# IWRL6432 register map
File version: 1.0
CPU: CM4 1.0, other endian, MPU, FPU, 3 interrupt priority bits
Registers are 32-bit, read-write, reset 0x0 unless marked. A register's access mark holds for its fields unless they carry their own. Offsets are from the block's base; [hi:lo] are bit positions; {n}, {i} and the like mark numbered series.

## HWA_CFG
Base 0x55010000
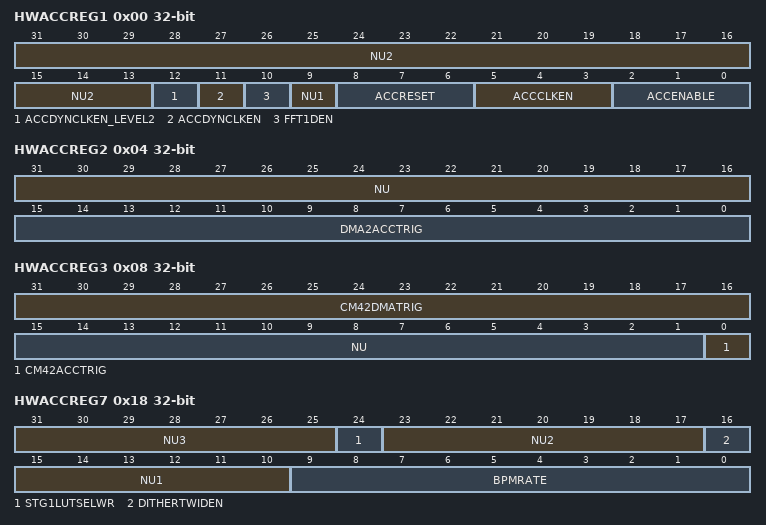
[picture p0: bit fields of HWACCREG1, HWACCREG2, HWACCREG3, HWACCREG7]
0x00 HWACCREG1
  [31:13] NU2
  [12] ACCDYNCLKEN_LEVEL2 — [12:12] Level 2 dynamic clock-gating control :- Setting this register bit to 1 will lead to further power saving by disabling clock during FSM wait state.
  [11] ACCDYNCLKEN — [11:11] Dynamic Clock-gating Control:Setting this register bit to 1 enables the capability to clock gate the Radar Accelerator core IPs (FFT and CFAR-CA datapath,CFAR-OS datapath, memory compression datapath) based on the ParamSet being executed.
  [10] FFT1DEN — [10:10] ADC buffer sharing mode This register is relevant where the Radar Hardware Accelerator is included in a single device along with the mmWave RF front-end. In such a case, during active chirp transmission and inline 1st dimension FFT processing, the ACCEL_MEM0 and ACCEL_MEM1 memories of the accelerator are shared as ping-pong ADC buffers. This register bit needs to be set during this time, so that while the Digital Front End writes ADC samples to the ping buffer, the accelerator automatically accesses (only) the pong buffer, and vice versa. At the end of the active transmission portion of a frame, this bit can be cleared, so that the accelerator has access to all the four local memories independently.
  [9] NU1
  [8:6] ACCRESET — [8:6] Software Reset Control: This register provides software reset control for the Radar Hardware Accelerator. The assertion of these register bits by the main processor will bring the Accelerator Engine to a known reset state. This is mostly applicable for resetting the accelerator in case of unexpected behavior. The sequence to be followed in case software reset is to write 111b to this register and then a 000b
  [5:3] ACCCLKEN — [5:3] Clock-gating Control: This register bit controls the enable/disable for the clock of the Radar Accelerator. This register bit can be set to 0 to clock-gate the accelerator when not using the accelerator. Before enabling the accelerator or before configuring the registers of accelerator, this register bit should be set to 111b first, so that the clock is available.
  [2:0] ACCENABLE — [2:0] Enable/Disable Control: A value of ACC_ENABLE = 111b enables the Radar Hardware Accelerator and any other value of the register keeps the Accelerator Engine in disabled state.
0x04 HWACCREG2
  [31:16] NU
  [15:0] DMA2ACCTRIG — [15:0] DMA trigger register: This register is relevant whenever DMA triggered mode is used (i.e., TRIGMODE = 011b). Whenever a DMA channel has finished copying input samples into the local memory of the accelerator and wants to trigger the accelerator, the procedure to follow is to use a second linked DMA channel to write a 16-bit one-hot signature into this register to trigger the accelerator. In DMA triggered mode, the State Machine keeps monitoring this 16-bit register and waits as long as a specific bit (see DMA2ACC_CHANNEL_TRIGSRC) in this register is zero. The second linked DMA channel writes a one-hot signature that sets the specific bit, so that the State Machine gets triggered and starts the accelerator operations for that parameter-set.
0x08 HWACCREG3
  [31:16] CM42DMATRIG — [31:16] Override accelerator Trigger to DMA.Can be used for triggering the first and second DMA transfer thorugh processor
  [15:1] NU
  [0] CM42ACCTRIG — [0:0] Software trigger bit: This register bit is relevant whenever software triggered mode is used (i.e., TRIGMODE = 001b). The main processor software can set this register bit, so that the State Machine gets triggered and starts the accelerator operations for that parameter-set.
0x0C HWACCREG4
  [31:0] SPARE — [31:0] Spare register
0x10 HWACCREG5
  [31:0] BPMPATTERNMSB — [31:0] BPM pattern MSB: Specifies the BPM pattern to be used to multiply the input samples if BPM removal is enabled
0x14 HWACCREG6
  [31:0] BPMPATTERNLSB — [31:0] BPM pattern LSB: Specifies the BPM pattern to be used to multiply the input samples if BPM removal is enabled
0x18 HWACCREG7
  [31:25] NU3
  [24] STG1LUTSELWR — [24:24] Select Window RAM or Internal RAM: The Internal RAM for Vector Multiplication mode is mapped to the same address space as the Window RAM. Hence, this register bit is required to specify which of these two needs to be selected, when loading the co-efficients via DMA or M4. 0 - Window RAM is selected 1 - Internal RAM for Vector Multiplication mode is selected. Keep this register bit as 0 always, except during the period when Internal RAM needs to be loaded.
  [23:17] NU2
  [16] DITHERTWIDEN — [16:16] Twiddle factor dithering enable: This register-bit is used to enable/disable dithering of twiddle factors in the FFT.
  [15:10] NU1
  [9:0] BPMRATE — [9:0] BPM rate: Specifies the number of input samples corresponding to each BPM bit. Minimum valid value for this register is 1.
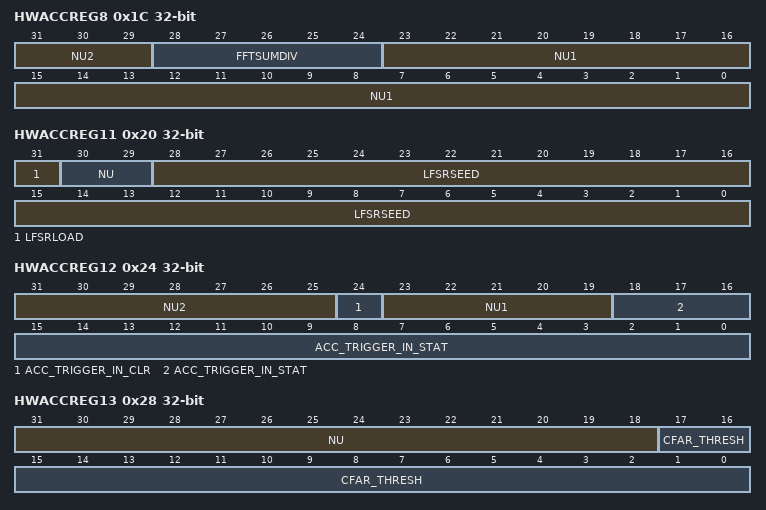
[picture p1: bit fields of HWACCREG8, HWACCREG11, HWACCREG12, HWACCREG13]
0x1C HWACCREG8
  [31:29] NU2
  [28:24] FFTSUMDIV — [28:24] Right-shifting for Sum Statistic: This register specifies how many LSBs to drop to convert the sum statistics to 24-bit value going to the Output Formatter
  [23:0] NU1
0x20 HWACCREG11
  [31] LFSRLOAD — [31:31] To load the LFSR seed, a pulse signal needs to be provided, by writing a 1 to the LFSR_LOAD register-bit. Self clearing
  [30:29] NU
  [28:0] LFSRSEED — [28:0] LFSR seed value (random pattern) for twiddle factor dithering,
0x24 HWACCREG12
  [31:25] NU2
  [24] ACC_TRIGGER_IN_CLR — [24:24] Clear trigger status read-only register: This register-bit when set clears the trigger status register ACC_TRIG_IN_STAT described above
  [23:19] NU1
  [18:0] ACC_TRIGGER_IN_STAT — [18:0] Debug register for trigger status: This is a read-only status register, which indicates the trigger status of the accelerator, i.e., whether a specific DMA trigger or a Ping-pong trigger or a SW trigger was ever received (refer TRIGMODE in HW_ACC_PARAM register set). The MSB 16 bits of this register indicate whether a trigger was received via DMA trigger method. The next two bits (i.e., bit indices 2 and 1) indicate the status of DFE ping-pong switch-based trigger and SW trigger respectively. The LSB bit is always 1 and can be ignored {DMA2ACCTRIG[15:0],adc_buffer_done,CM42ACCTRIG,1}
0x28 HWACCREG13
  [31:18] NU
  [17:0] CFAR_THRESH — [17:0] CFAR Threshold scale factor: This value is used to either multiply or add to the surrounding noise average to determine the threshold used for detection of the present cell under test. If logarithmic CFAR mode is disabled (i.e., in magnitude or magnitude-squared mode), then the register value is multiplied with the surrounding noise average to determine the threshold, else it is added to the surrounding noise average. In the former case, this 18-bit register is interpreted as a 14.4 value. In the latter case (i.e., logarithmic mode), the 18-bit register is interpreted as a 7.11 value.
0x2C HWACCREG14
  [31:0] PARAMDONESTAT — [31:0] Parameter-set done status: This read-only status register can be used by the main processor to see which parameter-sets are complete that led to the interrupt to the main processor. The individual bits in this 32-bit status register indicate which of the 32 parameter-sets have completed.
0x30 HWACCREG15
  [31:0] PARAMDONECLR — [31:0] Status bits in PARAMDONESTAT are not automatically cleared, but they can be individually cleared by writing to 32-bit register PARAMDONECLR.
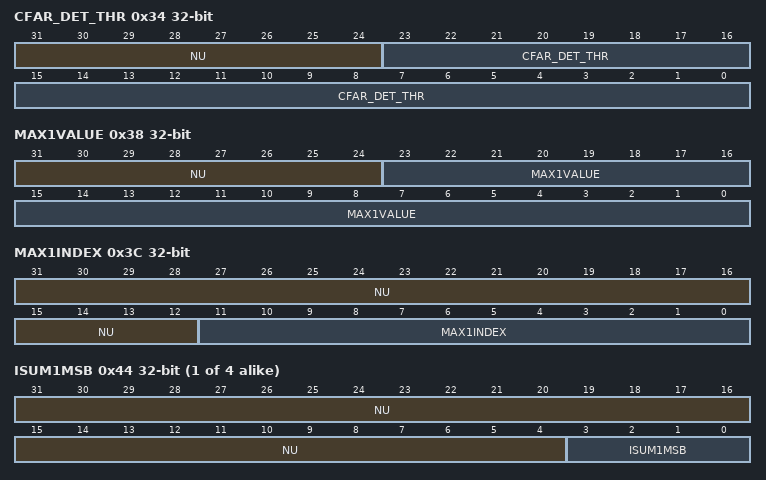
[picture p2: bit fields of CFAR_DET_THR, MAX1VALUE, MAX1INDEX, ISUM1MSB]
0x34 CFAR_DET_THR
  [31:24] NU
  [23:0] CFAR_DET_THR — [23:0] This register is used to specify the threshold used for the detection of the present cell under test during CFAR-CA mode when number of samples for left side and right side noise averaging is 0.
0x38 MAX1VALUE
  [31:24] NU
  [23:0] MAX1VALUE — [23:0] Max value: These registers contain the max value on a per-iteration basis. These registers are meaningful only when Magnitude or Log-Magnitude is enabled. Only the max values for up to four iterations are recorded in these registers. For larger number of iterations, use Statistics output mode (FFT_OUT_MODE in HW_ACC_PARAM register set).
0x3C MAX1INDEX
  [31:12] NU
  [11:0] MAX1INDEX — [11:0] Max index: These registers contain the max index on a per-iteration basis, corresponding to each max value in the MAXn_VALUE registers.
0x40 ISUM1LSB
  [31:0] ISUM1LSB — [31:0] Sum statistics: These registers contain the sum of the I outputs and Q outputs on a per-iteration basis. Only the statistics for up to four iterations are recorded in these registers. For larger number of iterations, use Statistics output mode (FFT_OUT_MODE in HW_ACC_PARAM register set).
{0x2C+0x18*i} ISUM{i}MSB (i=1..4)
  [31:4] NU
  [3:0] ISUM{i}MSB — [3:0] Refer ISUM1LSB
{0x30+0x18*i} QSUM{i}LSB (i=1..4)
  [31:0] QSUM{i}LSB — [31:0] Refer ISUM1LSB
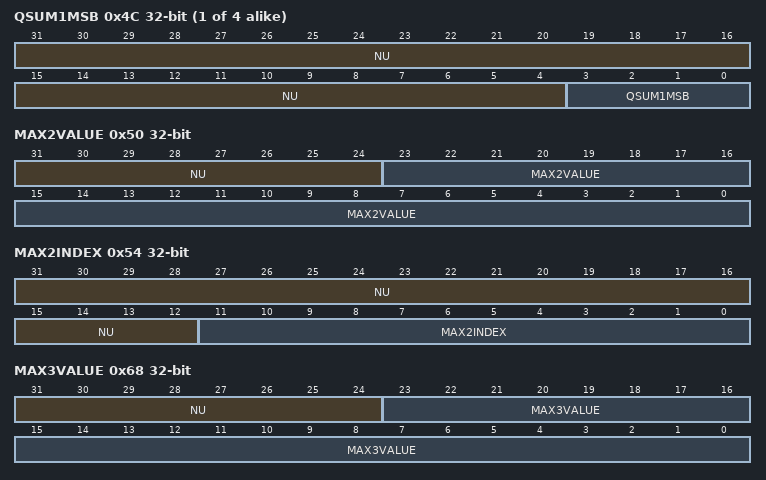
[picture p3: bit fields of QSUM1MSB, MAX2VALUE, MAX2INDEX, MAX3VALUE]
{0x34+0x18*i} QSUM{i}MSB (i=1..4)
  [31:4] NU
  [3:0] QSUM{i}MSB — [3:0] Refer ISUM1LSB
0x50 MAX2VALUE
  [31:24] NU
  [23:0] MAX2VALUE — [23:0] Refer MAX1VALUE
0x54 MAX2INDEX
  [31:12] NU
  [11:0] MAX2INDEX — [11:0] Refer MAX1INDEX
{0x28+0x18*i} ISUM{i}LSB (i=2..4)
  [31:0] ISUM{i}LSB — [31:0] Refer ISUM1LSB
0x68 MAX3VALUE
  [31:24] NU
  [23:0] MAX3VALUE — [23:0] Refer MAX1VALUE
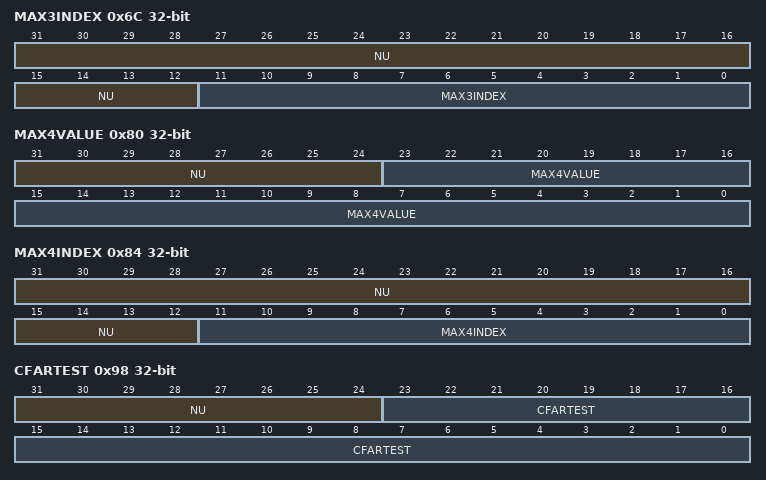
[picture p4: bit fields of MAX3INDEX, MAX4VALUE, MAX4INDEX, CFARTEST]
0x6C MAX3INDEX
  [31:12] NU
  [11:0] MAX3INDEX — [11:0] Refer MAX1INDEX
0x80 MAX4VALUE
  [31:24] NU
  [23:0] MAX4VALUE — [23:0] Refer MAX1INDEX
0x84 MAX4INDEX
  [31:12] NU
  [11:0] MAX4INDEX — [11:0] Refer MAX1VALUE
0x98 CFARTEST
  [31:24] NU
  [23:0] CFARTEST — [23:0] Reserved.TI internal
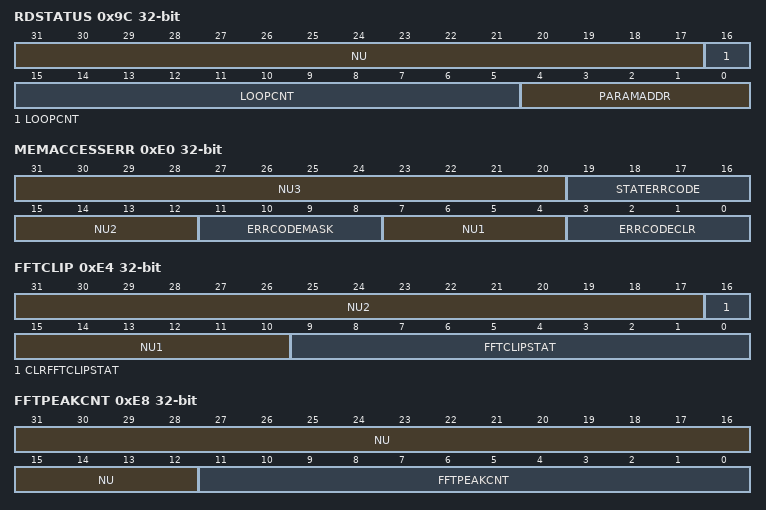
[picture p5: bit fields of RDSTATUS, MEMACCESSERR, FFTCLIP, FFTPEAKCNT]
0x9C RDSTATUS
  [31:17] NU
  [16:5] LOOPCNT — [16:5] Running value of the loop count when the HWA is executing from PARAM RAM . For Debug only
  [4:0] PARAMADDR — [4:0] Index of the current parameter set being executed from PARAM RAM . For Debug only
0xA0 SIGDMACH1DONE
  [31:0] SIGDMACH1DONE — [31:0] Signature for DMA channel 1 completion (tied to 0x0001 in HW). Linked DMA can copy from one of these SIG_DMACHx_DONE registers into DMA2ACC_TRIG register to set the appropriate register bit to signal the completion of DMA and trigger the accelerator
0xA4 SIGDMACH2DONE
  [31:0] SIGDMACH2DONE — [31:0] Signature for DMA channel 2 completion (tied to 0x0002 in HW)
0xA8 SIGDMACH3DONE
  [31:0] SIGDMACH3DONE — [31:0] Signature for DMA channel 3 completion (tied to 0x0004 in HW)
0xAC SIGDMACH4DONE
  [31:0] SIGDMACH4DONE — [31:0] Signature for DMA channel 4 completion (tied to 0x0008 in HW)
0xB0 SIGDMACH5DONE
  [31:0] SIGDMACH5DONE — [31:0] Signature for DMA channel 5 completion (tied to 0x0010 in HW)
0xB4 SIGDMACH6DONE
  [31:0] SIGDMACH6DONE — [31:0] Signature for DMA channel 6 completion (tied to 0x0020 in HW)
0xB8 SIGDMACH7DONE
  [31:0] SIGDMACH7DONE — [31:0] Signature for DMA channel 7 completion (tied to 0x0040 in HW)
0xBC SIGDMACH8DONE
  [31:0] SIGDMACH8DONE — [31:0] Signature for DMA channel 8 completion (tied to 0x0080 in HW)
0xC0 SIGDMACH9DONE
  [31:0] SIGDMACH9DONE — [31:0] Signature for DMA channel 9 completion (tied to 0x0100 in HW)
0xC4 SIGDMACH10DONE
  [31:0] SIGDMACH10DONE — [31:0] Signature for DMA channel 10 completion (tied to 0x0200 in HW)
0xC8 SIGDMACH11DONE
  [31:0] SIGDMACH11DONE — [31:0] Signature for DMA channel 11 completion (tied to 0x0040 in HW)
0xCC SIGDMACH12DONE
  [31:0] SIGDMACH12DONE — [31:0] Signature for DMA channel 12 completion (tied to 0x0080 in HW)
0xD0 SIGDMACH13DONE
  [31:0] SIGDMACH13DONE — [31:0] Signature for DMA channel 13 completion (tied to 0x1000 in HW)
0xD4 SIGDMACH14DONE
  [31:0] SIGDMACH14DONE — [31:0] Signature for DMA channel 14 completion (tied to 0x2000 in HW)
0xD8 SIGDMACH15DONE
  [31:0] SIGDMACH15DONE — [31:0] Signature for DMA channel 15 completion (tied to 0x4000 in HW)
0xDC SIGDMACH16DONE
  [31:0] SIGDMACH16DONE — [31:0] Signature for DMA channel 16 completion (tied to 0x8000 in HW)
0xE0 MEMACCESSERR
  [31:20] NU3
  [19:16] STATERRCODE — [19:16] Reserved.TI internal
  [15:12] NU2
  [11:8] ERRCODEMASK — [11:8] Reserved.TI internal
  [7:4] NU1
  [3:0] ERRCODECLR — [3:0] Reserved.TI internal
0xE4 FFTCLIP
  [31:17] NU2
  [16] CLRFFTCLIPSTAT — [16:16] FFTCLIPSTAT can be cleared by setting single-bit register CLRFFTCLIPSTAT, so that the saturation status indication gets cleared back to 0 and any subsequent saturation events can be freshly monitored.
  [15:10] NU1
  [9:0] FFTCLIPSTAT — [9:0] FFT Clip Status (read-only): This is a read-only status register, which indicates any saturation/clipping events that have happened in the FFT butterfly stages. Note that each of the 10 butterfly stages in the FFT can be programmed to either saturate the MSB or round the LSB. Whenever saturation of MSB is used in any stage, there is a possibility that that stage can saturate/clip samples. In that case, this saturation event is indicated in the corresponding bit in this status registert. If multiple FFTs are performed, this status register includes any saturation events happening in any of them.
0xE8 FFTPEAKCNT
  [31:12] NU
  [11:0] FFTPEAKCNT — [11:0] CFAR Detected Peak Count: This is a read-only register that contains the number of detected peaks that are logged in the destination memory, when CFAR Engine is configured in Detected Peaks List mode.
{0xE8+4i} HWACCREG{i}RD (i=1..3)
  [31:0] HWACCREG{i}RD — [31:0] Reserved.TI internal
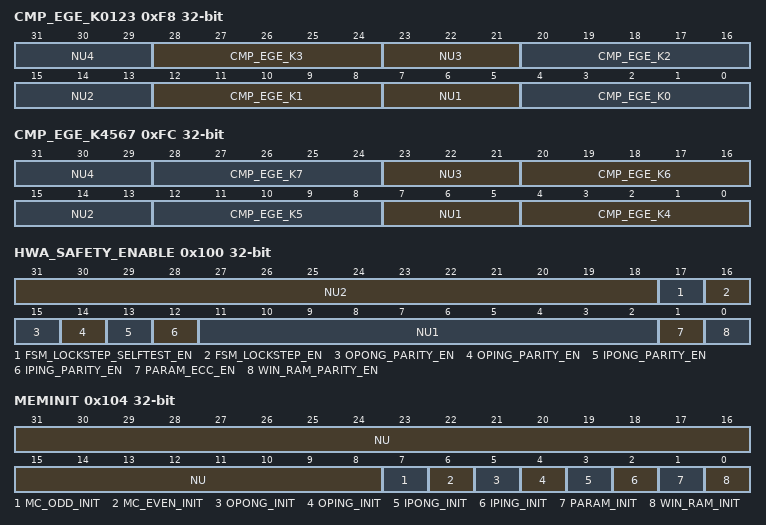
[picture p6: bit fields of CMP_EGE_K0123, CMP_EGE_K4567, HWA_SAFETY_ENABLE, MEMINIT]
0xF8 CMP_EGE_K0123
  [8n-1:8n-3] NU{n} (n=1..4) — [{8n-1}:{8n-3}] Reserved.TI internal
  [28:24] CMP_EGE_K3 — [28:24] EGE K-param for the 4th accumulator
  [20:16] CMP_EGE_K2 — [20:16] EGE K-param for the 3rd accumulator
  [12:8] CMP_EGE_K1 — [12:8] EGE K-param for the 2nd accumulator
  [4:0] CMP_EGE_K0 — [4:0] EGE K-param for the 1st accumulator
0xFC CMP_EGE_K4567
  [8n-1:8n-3] NU{n} (n=1..4) — [{8n-1}:{8n-3}] Reserved.TI internal
  [8n-28:8n-32] CMP_EGE_K{n} (n=4..7) — [{8n-28}:{8n-32}] EGE K-param for the {n+1}th accumulator
0x100 HWA_SAFETY_ENABLE
  [31:18] NU2
  [17] FSM_LOCKSTEP_SELFTEST_EN — [17:17] 1: Enable Selftest for Accelerator FSM
  [16] FSM_LOCKSTEP_EN — [16:16] 1: Enable Lockstep for Accelerator FSM
  [15] OPONG_PARITY_EN — [15:15] 1: Enable PARITY for ACCEL_MEM3
  [14] OPING_PARITY_EN — [14:14] 1: Enable PARITY for ACCEL_MEM2
  [13] IPONG_PARITY_EN — [13:13] 1: Enable PARITY for ACCEL_MEM1
  [12] IPING_PARITY_EN — [12:12] 1: Enable PARITY for ACCEL_MEM0
  [11:2] NU1
  [1] PARAM_ECC_EN — [1:1] Not used.
  [0] WIN_RAM_PARITY_EN — [0:0] 1: Enable PARITY for Window RAM
0x104 MEMINIT
  [31:8] NU
  [7] MC_ODD_INIT — [7:7] 1: Start initialising MEM_COMPRESSION_ODD_RAM with all '0's
  [6] MC_EVEN_INIT — [6:6] 1: Start initialising MEM_COMPRESSION_EVEN_RAM with all '0's
  [5] OPONG_INIT — [5:5] 1: Start initialising ACCEL_MEM3 with all '0's
  [4] OPING_INIT — [4:4] 1: Start initialising ACCEL_MEM2 with all '0's
  [3] IPONG_INIT — [3:3] 1: Start initialising ACCEL_MEM1 with all '0's
  [2] IPING_INIT — [2:2] 1: Start initialising ACCEL_MEM0 with all '0's
  [1] PARAM_INIT — [1:1] 1: Start initialising Parameter set RAM with all '0's
  [0] WIN_RAM_INIT — [0:0] 1: Start initialising Window RAM with all '0's
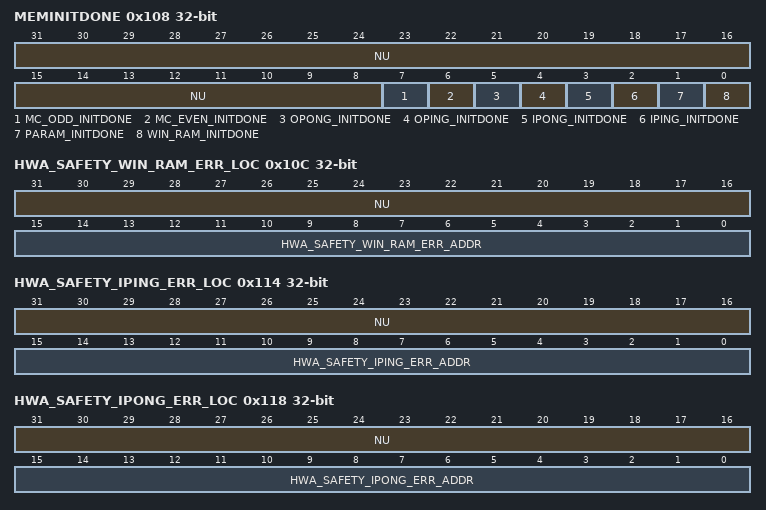
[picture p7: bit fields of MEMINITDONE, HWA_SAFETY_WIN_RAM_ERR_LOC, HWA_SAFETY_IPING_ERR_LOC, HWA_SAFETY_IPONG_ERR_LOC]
0x108 MEMINITDONE
  [31:8] NU
  [7] MC_ODD_INITDONE — [7:7] 1: Init done status for MEM_COMPRESSION_ODD_RAM
  [6] MC_EVEN_INITDONE — [6:6] 1: Init done status for MEM_COMPRESSION_EVEN_RAM
  [5] OPONG_INITDONE — [5:5] 1: Init done status for ACCEL_MEM3
  [4] OPING_INITDONE — [4:4] 1: Init done status for ACCEL_MEM2
  [3] IPONG_INITDONE — [3:3] 1: Init done status for ACCEL_MEM1
  [2] IPING_INITDONE — [2:2] 1: Init done status for ACCEL_MEM0
  [1] PARAM_INITDONE — [1:1] 1: Init done status for Parameter set RAM
  [0] WIN_RAM_INITDONE — [0:0] 1: Init done status for Window RAM
0x10C HWA_SAFETY_WIN_RAM_ERR_LOC
  [31:16] NU
  [15:0] HWA_SAFETY_WIN_RAM_ERR_ADDR — [15:0] [Debug] Address of parity error location within Window RAM
0x110 HWA_SAFETY_PARAM_RAM_ERR_LOC
  [31:0] SPARE — [31:0] Reserved.TI internal
0x114 HWA_SAFETY_IPING_ERR_LOC
  [31:16] NU
  [15:0] HWA_SAFETY_IPING_ERR_ADDR — [15:0] [Debug ]Address of parity error location within ACCEL_MEM0 (rows 0-1023)
0x118 HWA_SAFETY_IPONG_ERR_LOC
  [31:16] NU
  [15:0] HWA_SAFETY_IPONG_ERR_ADDR — [15:0] [Debug ]Address of parity error location within ACCEL_MEM1 (rows 0-1023)
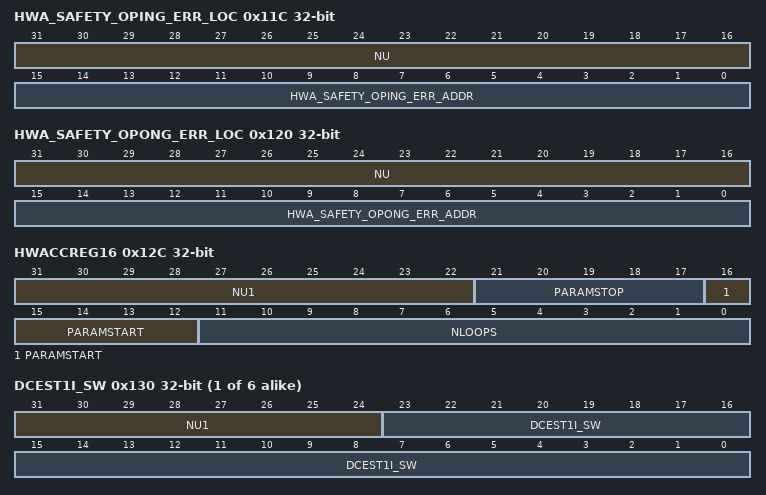
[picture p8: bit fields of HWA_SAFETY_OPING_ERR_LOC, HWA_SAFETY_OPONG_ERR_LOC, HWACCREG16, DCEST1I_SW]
0x11C HWA_SAFETY_OPING_ERR_LOC
  [31:16] NU
  [15:0] HWA_SAFETY_OPING_ERR_ADDR — [15:0] [Debug ]Address of parity error location within ACCEL_MEM2 (rows 0-1023)
0x120 HWA_SAFETY_OPONG_ERR_LOC
  [31:16] NU
  [15:0] HWA_SAFETY_OPONG_ERR_ADDR — [15:0] [Debug ]Address of parity error location within ACCEL_MEM3 (rows 0-1023)
0x124 FFTINTMEMWRDATA
  [31:0] FFTINTMEMWRDATA — [31:0] Reserved.TI internal
0x128 FFTINTMEMRDDATA
  [31:0] FFTINTMEMRDDATA — [31:0] Reserved.TI internal
0x12C HWACCREG16
  [31:22] NU1
  [21:17] PARAMSTOP — [21:17] These registers are used to control the start and stop index of the parameter-set through which the state machine loops through. The state machine starts at the parameter-set specified by PARAM_START and loads each parameter-set one after another and runs the accelerator as per that configuration. When the state machine reaches the parameter-set specified by PARAM_STOP, it loops back to the start index as specified by PARAM_START.
  [16:12] PARAMSTART — [16:12] These registers are used to control the start and stop index of the parameter-set through which the state machine loops through. The state machine starts at the parameter-set specified by PARAM_START and loads each parameter-set one after another and runs the accelerator as per that configuration. When the state machine reaches the parameter-set specified by PARAM_STOP, it loops back to the start index as specified by PARAM_START.
  [11:0] NLOOPS — [11:0] Number of loops: This register controls the number of times the State Machine will loop through the parameter-sets (from a programmed start index till a programmed end index) and run them. The maximum number of times the loop can be made is run is 4094. A value of zero programmed in this register means that the looping mechanism is disabled.
{0x12C+4i} DCEST{i}I_SW (i=1..6)
  [31:24] NU1
  [23:0] DCEST{i}I_SW — [23:0] This register holds the software programmed dc value I to be subtracted from incoming sample for bcnt = {i-1}.
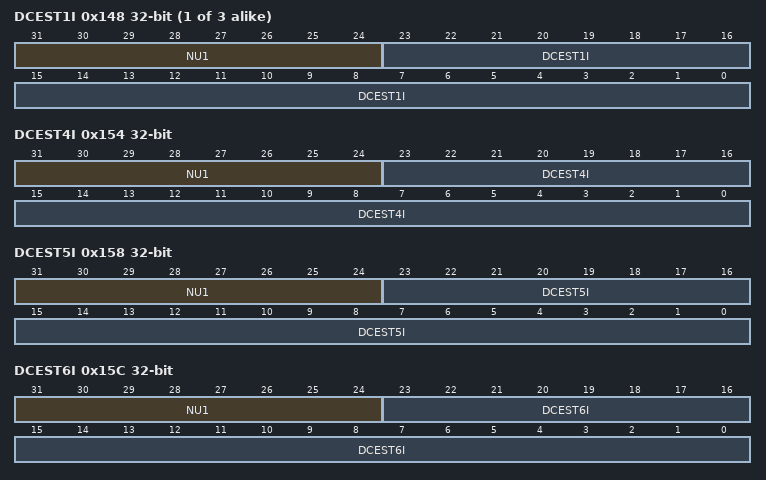
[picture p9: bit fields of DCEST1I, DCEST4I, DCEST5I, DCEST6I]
{0x144+4i} DCEST{i}I (i=1..3)
  [31:24] NU1
  [23:0] DCEST{i}I — [23:0] This register holds the estimated dc value I to be subtracted from incoming sample for bcnt ={i-1} .
0x154 DCEST4I
  [31:24] NU1
  [23:0] DCEST4I — [23:0] This register holds the estimated dc value I to be subtracted from incoming sample for bcnt =3.
0x158 DCEST5I
  [31:24] NU1
  [23:0] DCEST5I — [23:0] This register holds the estimated dc value I to be subtracted from incoming sample for bcnt =4 .
0x15C DCEST6I
  [31:24] NU1
  [23:0] DCEST6I — [23:0] This register holds the estimated dc value I to be subtracted from incoming sample for bcnt =5 .
{0x158+8i} DC_ACC{i}I_LSB (i=1..6)
  [31:0] DC_ACC{i}I_LSB — [31:0] This register provides the LSB 32 bits value of DC accumulator I channel for bcnt={i-1}
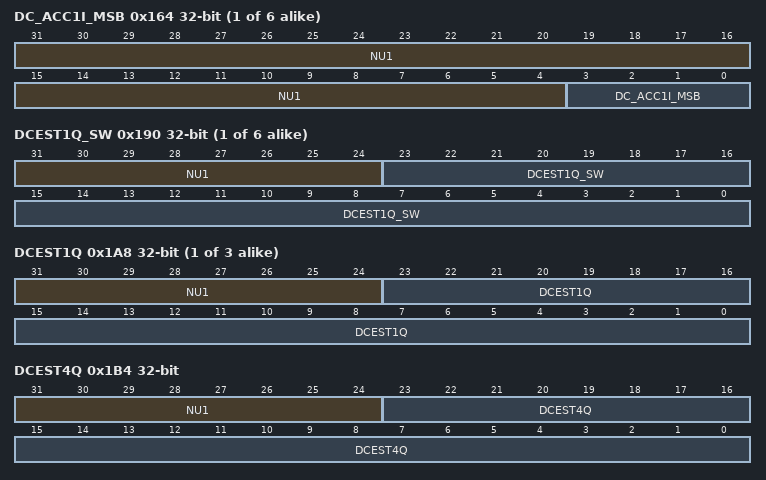
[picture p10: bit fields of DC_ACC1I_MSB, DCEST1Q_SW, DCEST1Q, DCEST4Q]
{0x15C+8i} DC_ACC{i}I_MSB (i=1..6)
  [31:4] NU1
  [3:0] DC_ACC{i}I_MSB — [3:0] This register provides the MSB 4 bits value of DC accumulator I channel for bcnt={i-1}
{0x18C+4i} DCEST{i}Q_SW (i=1..6)
  [31:24] NU1
  [23:0] DCEST{i}Q_SW — [23:0] This register holds the software programmed dc value Q to be subtracted from incoming sample for bcnt = {i-1}.
{0x1A4+4i} DCEST{i}Q (i=1..3)
  [31:24] NU1
  [23:0] DCEST{i}Q — [23:0] This register holds the estimated dc value Q to be subtracted from incoming sample for bcnt ={i-1} .
0x1B4 DCEST4Q
  [31:24] NU1
  [23:0] DCEST4Q — [23:0] This register holds the estimated dc value Q to be subtracted from incoming sample for bcnt =3.
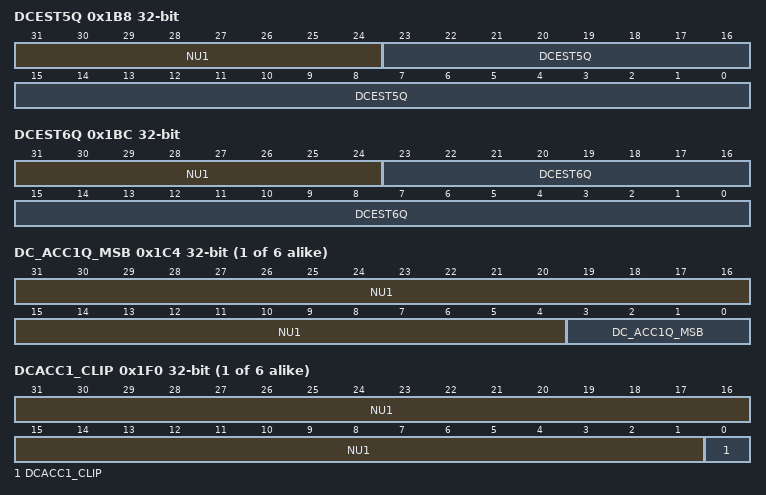
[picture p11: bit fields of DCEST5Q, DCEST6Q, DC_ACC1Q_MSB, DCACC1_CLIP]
0x1B8 DCEST5Q
  [31:24] NU1
  [23:0] DCEST5Q — [23:0] This register holds the estimated dc value Q to be subtracted from incoming sample for bcnt =4 .
0x1BC DCEST6Q
  [31:24] NU1
  [23:0] DCEST6Q — [23:0] This register holds the estimated dc value Q to be subtracted from incoming sample for bcnt =5 .
{0x1B8+8i} DC_ACC{i}Q_LSB (i=1..6)
  [31:0] DC_ACC{i}Q_LSB — [31:0] This register provides the LSB 32 bits value of DC accumulator Q channel for bcnt={i-1}
{0x1BC+8i} DC_ACC{i}Q_MSB (i=1..6)
  [31:4] NU1
  [3:0] DC_ACC{i}Q_MSB — [3:0] This register provides the MSB 4 bits value of DC accumulator Q channel for bcnt={i-1}
{0x1EC+4i} DCACC{i}_CLIP (i=1..6)
  [31:1] NU1
  [0] DCACC{i}_CLIP — [0:0] This register contains the clip status of both I/Q of DC accumulators for bcnt ={i-1}
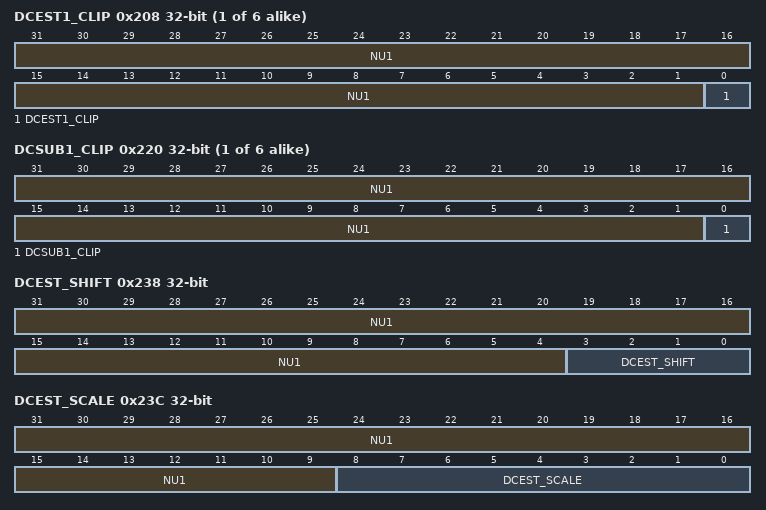
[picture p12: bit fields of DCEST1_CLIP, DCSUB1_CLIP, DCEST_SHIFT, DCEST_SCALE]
{0x204+4i} DCEST{i}_CLIP (i=1..6)
  [31:1] NU1
  [0] DCEST{i}_CLIP — [0:0] This register contains the clip status of both I/Q DC estimates for bcnt ={i-1}
{0x21C+4i} DCSUB{i}_CLIP (i=1..6)
  [31:1] NU1
  [0] DCSUB{i}_CLIP — [0:0] Indicates the DC subtraction clip status for bcnt ={i-1}
0x238 DCEST_SHIFT
  [31:4] NU1
  [3:0] DCEST_SHIFT — [3:0] Programmable shift applied to all 6 accumulator outputs. Cannot be bypassed. Scaled accumulator output is shifted by 2^( 2+DCEST_SHIFT). For DCEST_SHIFT = 15 also gives 2^(24) and not 25 (saturate at 24)
0x23C DCEST_SCALE
  [31:9] NU1
  [8:0] DCEST_SCALE — [8:0] 9-bit scale applied to all 6 accumulators. Multiplies the accumulator output by DCEST_SCALE/256.This is followed by right shift and truncation.Default value is 256 giving a scale of 1.0. Setting it to 128, gives a scale of 0.5
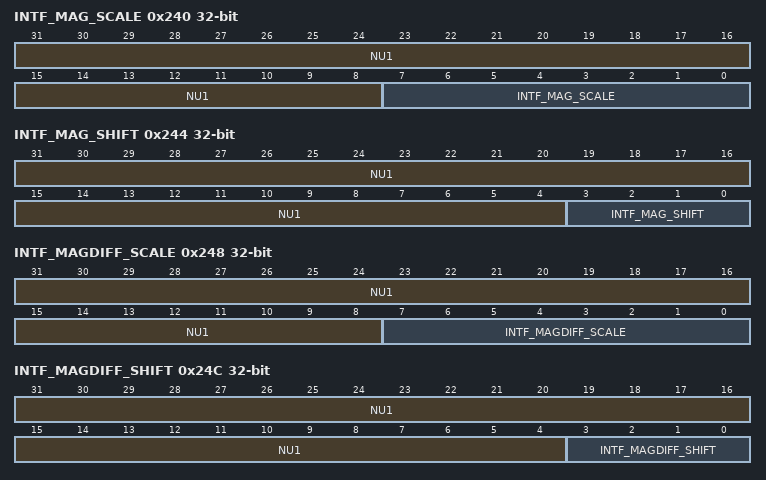
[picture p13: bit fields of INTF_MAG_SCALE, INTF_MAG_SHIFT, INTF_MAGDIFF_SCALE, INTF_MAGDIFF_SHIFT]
0x240 INTF_MAG_SCALE
  [31:8] NU1
  [7:0] INTF_MAG_SCALE — [7:0] Unsigned scaler (5.3) applied to INTERFSUM_MAGn from interference statistics block.Default 8= scale of 1.0
0x244 INTF_MAG_SHIFT
  [31:4] NU1
  [3:0] INTF_MAG_SHIFT — [3:0] Right shift applied after scaling ΓÇô 2^(4+INTERFSUM_MAG_SHIFT). Can t be more than 2^(17).
0x248 INTF_MAGDIFF_SCALE
  [31:8] NU1
  [7:0] INTF_MAGDIFF_SCALE — [7:0] Unsigned scaler (5.3) applied to INTERFSUM_MAGDIFFn from interference statistics block.Default 8= scale of 1.0
0x24C INTF_MAGDIFF_SHIFT
  [31:4] NU1
  [3:0] INTF_MAGDIFF_SHIFT — [3:0] Right shift applied after scaling ΓÇô 2^(4+INTERFSUM_MAGDIFF_SHIFT). Can t be more than 2^(17).
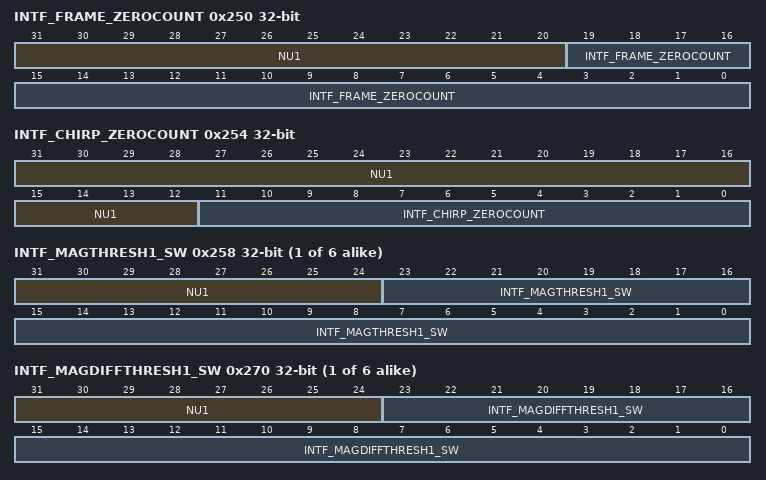
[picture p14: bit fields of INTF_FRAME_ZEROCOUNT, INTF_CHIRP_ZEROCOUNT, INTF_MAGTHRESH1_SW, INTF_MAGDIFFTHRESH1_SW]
0x250 INTF_FRAME_ZEROCOUNT
  [31:20] NU1
  [19:0] INTF_FRAME_ZEROCOUNT — [19:0] Number of samples that exceeded the threshold in a frame
0x254 INTF_CHIRP_ZEROCOUNT
  [31:12] NU1
  [11:0] INTF_CHIRP_ZEROCOUNT — [11:0] Number of samples that exceeded the threshold in a chirp
{0x254+4i} INTF_MAGTHRESH{i}_SW (i=1..6)
  [31:24] NU1
  [23:0] INTF_MAGTHRESH{i}_SW — [23:0] This register provides software programmed interference magnitude threshold value for bcnt ={i-1}
{0x26C+4i} INTF_MAGDIFFTHRESH{i}_SW (i=1..6)
  [31:24] NU1
  [23:0] INTF_MAGDIFFTHRESH{i}_SW — [23:0] This register provides software programmed interference magnitude difference threshold value for bcnt ={i-1}
{0x280+8i} INTF_MAGACC{i}_LSB (i=1..6)
  [31:0] INTF_MAGACC{i}_LSB — [31:0] This register contains the accumulator value of the interference magnitude (LSB 32 bits) for bcnt = {i-1}
{0x284+8i} INTF_MAGACC{i}_MSB (i=1..6)
  [31:4] NU1
  [3:0] INTF_MAGACC{i}_MSB — [3:0] This register contains the accumulator value of the interference magnitude (MSB 4 bits) for bcnt = {i-1}
{0x2B0+8i} INTF_MAGDIFFACC{i}_LSB (i=1..6)
  [31:0] INTF_MAGDIFFACC{i}_LSB — [31:0] This register contains the accumulator value of the interference magnitude difference (LSB 32 bits) for bcnt = {i-1}
{0x2B4+8i} INTF_MAGDIFFACC{i}_MSB (i=1..6)
  [31:4] NU1
  [3:0] INTF_MAGDIFFACC{i}_MSB — [3:0] This register contains the accumulator value of the interference magnitude difference (MSB 4 bits) for bcnt = {i-1}
{0x2E4+4i} INTF_MAGACC{i}_CLIP (i=1..6)
  [31:1] NU1
  [0] INTF_MAGACC{i}_CLIP — [0:0] Interference magnitude accumulator clip status
{0x2FC+4i} INTF_MAGDIFFACC{i}_CLIP (i=1..6)
  [31:1] NU1
  [0] INTF_MAGDIFFACC{i}_CLIP — [0:0] Interference magnitude difference accumulator clip status
{0x314+4i} INTF_MAGTHRESH{i} (i=1..6)
  [31:24] NU1
  [23:0] INTF_MAGTHRESH{i} — [23:0] Indicates interference magnitude threshold by interference statistics for bcnt ={i-1}
{0x32C+4i} INTF_MAGDIFFTHRESH{i} (i=1..6)
  [31:24] NU1
  [23:0] INTF_MAGDIFFTHRESH{i} — [23:0] Indicates interference magnitude difference threshold by interference statistics for bcnt ={i-1}
0x348 INTF_SUMMAGTHRESH
  [31:24] NU1
  [23:0] INTF_SUMMAGTHRESH — [23:0] Indicates the sum of mag values ; only Configured BCNT mag values are added
0x34C INTF_SUMMAGDIFFTHRESH
  [31:24] NU1
  [23:0] INTF_SUMMAGDIFFTHRESH — [23:0] Indicates the sum of magdiff values ; only Configured BCNT magdiff values are added
0x350 INTF_SUMMAGTHRESH_CLIP
  [31:1] NU1
  [0] INTF_SUMMAGTHRESH_CLIP — [0:0] Indicates the clip status of sum of magnitude threshold values
0x354 INTF_SUMMAGDIFFTHRESH_CLIP
  [31:1] NU1
  [0] INTF_SUMMAGDIFFTHRESH_CLIP — [0:0] Indicates the clip status of sum of magnitude difference threshold values
0x358 CMULTSCALE1I
  [31:21] NU
  [20:0] CMULTSCALE1I — [20:0] In CMULT_MODE : 101 , the input samples are multiplied by a different complex scalar CMULTSCALE1I, CMULTSCALE1Q to CMULTSCALE6I, CMULTSCALE6Q per-iteration based on REG_BCNT. Else, a constant complex scalar CMULTSCALE1I and CMULTSCALEQI is applied to all sample across all iterations.
{0x354+4i} CMULTSCALE{i}I (i=2..6)
  [31:21] NU1
  [20:0] CMULTSCALE{i}I — [20:0] In CMULT_MODE : 101 , the input samples are multiplied by a different complex scalar CMULTSCALE1I, CMULTSCALE1Q to CMULTSCALE6I, CMULTSCALE6Q per-iteration based on REG_BCNT. Else, a constant complex scalar CMULTSCALE1I and CMULTSCALEQI is applied to all sample across all iterations.
0x370 CMULTSCALE1Q
  [31:21] NU
  [20:0] CMULTSCALE1Q — [20:0] In CMULT_MODE : 101 , the input samples are multiplied by a different complex scalar CMULTSCALE1I, CMULTSCALE1Q to CMULTSCALE6I, CMULTSCALE6Q per-iteration based on REG_BCNT. Else, a constant complex scalar CMULTSCALE1I and CMULTSCALEQI is applied to all sample across all iterations.
{0x36C+4i} CMULTSCALE{i}Q (i=2..6)
  [31:21] NU1
  [20:0] CMULTSCALE{i}Q — [20:0] In CMULT_MODE : 101 , the input samples are multiplied by a different complex scalar CMULTSCALE1I, CMULTSCALE1Q to CMULTSCALE6I, CMULTSCALE6Q per-iteration based on REG_BCNT. Else, a constant complex scalar CMULTSCALE1I and CMULTSCALEQI is applied to all sample across all iterations.
0x388 CLR_MISC_CLIP
  [31:1] NU1
  [0] CLR_MISC_CLIP — [0:0] This clears the following clip register :- dc_acc_clip_status dc_est_clip_status intf_stats_mag_accumulator_clip_status Intf_stats_magdiff_accumulator_clip_status intf_stats_thresh_mag_clip_status intf_stats_thresh_magdiff_clip_status ip_formatter_clip_status op_formatter_clip_status intf_stats_sum_mag_val_clip_status intf_stats_sum_magdiff_val_clip_status Its a self clearing bit
0x38C FFTINTMEMADDR
  [31:25] NU3 — [31:25] Reserved.TI internal
  [24] FFT_INT_MEM_RD — [24:24] Reserved.TI internal
  [23:17] NU2 — [23:17] Reserved.TI internal
  [16] FFT_INT_MEM_EN — [16:16] Reserved.TI internal
  [15:12] NU1 — [15:12] Reserved.TI internal
  [11:9] FFT_INT_MEM_SEL — [11:9] Reserved.TI internal
  [8:0] FFT_INT_MEM_ADDR — [8:0] Reserved.TI internal
0x390 INTF_STATS_RESET_SW
  [31:1] NU1
  [0] INTF_STATS_RESET_SW — [0:0] SW reset for Interference statistics module. Its a self clearing bit.
0x394 DCEST_RESET_SW
  [31:1] NU1
  [0] DCEST_RESET_SW — [0:0] Reset for all 6 DC estimation accumulators.Its a self clearing bit.
0x398 IP_OP_FORMATTER_CLIP_STATUS
  [31:17] NU2
  [16] OP_FORMATTER_CLIP_STATUS — [16:16] Indicates output formatter clip status
  [15:1] NU1
  [0] IP_FORMATTER_CLIP_STATUS — [0:0] Indicates input formatter clip status
{0x398+4i} INTF_MAGTHRESH{i}_CLIP (i=1..6)
  [31:1] NU1
  [0] INTF_MAGTHRESH{i}_CLIP — [0:0] Interference magnitude threshold clip status
{0x3B0+4i} INTF_MAGDIFFTHRESH{i}_CLIP (i=1..6)
  [31:1] NU1
  [0] INTF_MAGDIFFTHRESH{i}_CLIP — [0:0] Interference magnitude difference threshold clip status
0x3CC HWA_SAFETY_ERR_MASK
  [31:10] NU1
  [9] HWA_SAFETY_ACCESS_ERR_MASK_OPONG_RAM — [9:9] When 1'b1 : ACCEL_MEM3 access error is masked.1'b0 : ACCEL_MEM3 access error is not masked
  [8] HWA_SAFETY_ACCESS_ERR_MASK_OPING_RAM — [8:8] When 1'b1 : ACCEL_MEM2 access error is masked.1'b0 : ACCEL_MEM2 access error is not masked
  [7] HWA_SAFETY_ACCESS_ERR_MASK_IPONG_RAM — [7:7] When 1'b1 : ACCEL_MEM1 access error is masked.1'b0 : ACCEL_MEM1 access error is not masked
  [6] HWA_SAFETY_ACCESS_ERR_MASK_IPING_RAM — [6:6] When 1'b1 : ACCEL_MEM0 access error is masked.1'b0 : ACCEL_MEM0 access error is not masked
  [5] HWA_SAFETY_PARITY_ERR_MASK_OPONG_RAM — [5:5] When 1'b1 : ACCEL_MEM3 parity error is masked.1'b0 : ACCEL_MEM03 parity error is not masked
  [4] HWA_SAFETY_PARITY_ERR_MASK_OPING_RAM — [4:4] When 1'b1 : ACCEL_MEM2 parity error is masked.1'b0 : ACCEL_MEM2 parity error is not masked
  [3] HWA_SAFETY_PARITY_ERR_MASK_IPONG_RAM — [3:3] When 1'b1 : ACCEL_MEM1 parity error is masked.1'b0 : ACCEL_MEM1 parity error is not masked
  [2] HWA_SAFETY_PARITY_ERR_MASK_IPING_RAM — [2:2] When 1'b1 : ACCEL_MEM0 parity error is masked.1'b0 : ACCEL_MEM0 parity error is not masked
  [1] HWA_SAFETY_PARITY_ERR_MASK_WINDOW_RAM — [1:1] When 1'b1 : Window RAM parity error is masked.1'b0 : Window RAM parity error is not masked
  [0] HWA_SAFETY_ERR_MASK_FSM_LOCKSTEP — [0:0] When 1'b1 : FSM lockstep error is masked.1'b0 : FSM lockstep error is not masked
0x3D0 HWA_SAFETY_ERR_STATUS
  [31:10] NU1
  [9] HWA_SAFETY_ACCESS_ERR_STATUS_OPONG_RAM — [9:9] Indicates the ACCEL_MEM3 access error (Masked status)
  [8] HWA_SAFETY_ACCESS_ERR_STATUS_OPING_RAM — [8:8] Indicates the ACCEL_MEM2 access error (Masked status)
  [7] HWA_SAFETY_ACCESS_ERR_STATUS_IPONG_RAM — [7:7] Indicates the ACCEL_MEM1 access error (Masked status)
  [6] HWA_SAFETY_ACCESS_ERR_STATUS_IPING_RAM — [6:6] Indicates the ACCEL_MEM0 access error (Masked status)
  [5] HWA_SAFETY_PARITY_ERR_STATUS_OPONG_RAM — [5:5] Indicates the ACCEL_MEM3 parity error (Masked status)
  [4] HWA_SAFETY_PARITY_ERR_STATUS_OPING_RAM — [4:4] Indicates the ACCEL_MEM2 parity error (Masked status)
  [3] HWA_SAFETY_PARITY_ERR_STATUS_IPONG_RAM — [3:3] Indicates the ACCEL_MEM1 parity error (Masked status)
  [2] HWA_SAFETY_PARITY_ERR_STATUS_IPING_RAM — [2:2] Indicates the ACCEL_MEM0 parity error (Masked status)
  [1] HWA_SAFETY_PARITY_ERR_STATUS_WINDOW_RAM — [1:1] Indicates the Window RAM parity error (Masked status)
  [0] HWA_SAFETY_ERR_STATUS_FSM_LOCKSTEP — [0:0] Indicates the FSM lockstep error (Masked status)
0x3D4 HWA_SAFETY_ERR_STATUS_RAW
  [31:10] NU1
  [9] HWA_SAFETY_ACCESS_ERR_STATUS_RAW_OPONG_RAM — [9:9] Indicates the ACCEL_MEM3 access error (raw status).Set irrespective of HWA_SAFETY_ERR_MASK bit 9
  [8] HWA_SAFETY_ACCESS_ERR_STATUS_RAW_OPING_RAM — [8:8] Indicates the ACCEL_MEM2 access error (raw status).Set irrespective of HWA_SAFETY_ERR_MASK bit 8
  [7] HWA_SAFETY_ACCESS_ERR_STATUS_RAW_IPONG_RAM — [7:7] Indicates the ACCEL_MEM1 access error (raw status).Set irrespective of HWA_SAFETY_ERR_MASK bit 7
  [6] HWA_SAFETY_ACCESS_ERR_STATUS_RAW_IPING_RAM — [6:6] Indicates the ACCEL_MEM0 access error (raw status).Set irrespective of HWA_SAFETY_ERR_MASK bit 6
  [5] HWA_SAFETY_PARITY_ERR_STATUS_RAW_OPONG_RAM — [5:5] Indicates the ACCEL_MEM3 parity error (raw status).Set irrespective of HWA_SAFETY_ERR_MASK bit 5
  [4] HWA_SAFETY_PARITY_ERR_STATUS_RAW_OPING_RAM — [4:4] Indicates the ACCEL_MEM2 parity error (raw status).Set irrespective of HWA_SAFETY_ERR_MASK bit 4
  [3] HWA_SAFETY_PARITY_ERR_STATUS_RAW_IPONG_RAM — [3:3] Indicates the ACCEL_MEM1 parity error (raw status).Set irrespective of HWA_SAFETY_ERR_MASK bit 3
  [2] HWA_SAFETY_PARITY_ERR_STATUS_RAW_IPING_RAM — [2:2] Indicates the ACCEL_MEM0 parity error (raw status).Set irrespective of HWA_SAFETY_ERR_MASK bit 2
  [1] HWA_SAFETY_PARITY_ERR_STATUS_RAW_WINDOW_RAM — [1:1] Indicates the Window RAM parity error (raw status).Set irrespective of HWA_SAFETY_ERR_MASK bit 1
  [0] HWA_SAFETY_ERR_STATUS_RAW_FSM_LOCKSTEP — [0:0] Indicates the FSM lockstep error (raw status).Set irrespective of HWA_SAFETY_ERR_MASK bit 0
